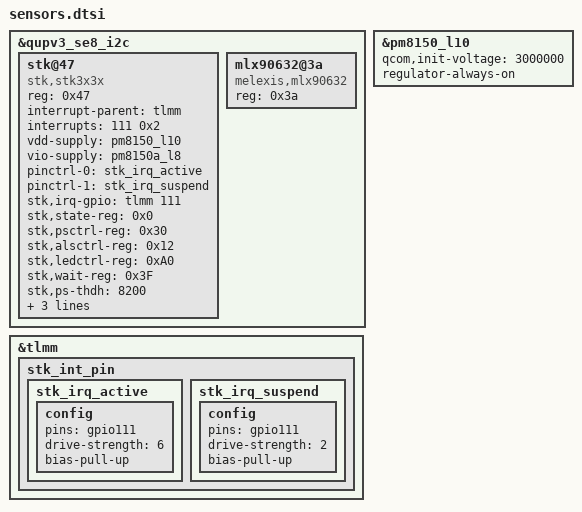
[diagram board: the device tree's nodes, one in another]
/*
 * nubia overwrite dts
 */

&qupv3_se8_i2c {
	status = "ok";
	stk@47 {
		compatible = "stk,stk3x3x";
		reg = <0x47>;
		interrupt-parent = <&tlmm>;
		interrupts = <111 0x2>;
		vdd-supply = <&pm8150_l10>; /*3.0v*/
		vio-supply = <&pm8150a_l8>; /*1.8v*/
		pinctrl-names = "stk_irq_active","stk_irq_suspend";
		pinctrl-0 = <&stk_irq_active>;
		pinctrl-1 = <&stk_irq_suspend>;
		stk,irq-gpio = <&tlmm 111 0x02>;
		stk,state-reg = <0x0>;
		stk,psctrl-reg = <0x30>;
		stk,alsctrl-reg = <0x12>;
		stk,ledctrl-reg = <0xA0>;
		stk,wait-reg = <0x3F>;
		stk,ps-thdh = <8200>;
		stk,ps-thdl = <8000>;
		stk,transmittance = <500>;
		stk,use-fir;
	};

	mlx90632@3a  {
		compatible = "melexis,mlx90632";
		reg = <0x3a>;
	};
};

&pm8150_l10 {
    status = "ok";
    qcom,init-voltage = <3000000>;
    regulator-always-on;
};
&tlmm {
	stk_int_pin {
		stk_irq_active: stk_irq_active {
			config {
				pins = "gpio111";
				drive-strength = <6>;
				bias-pull-up;
			};
		};
		stk_irq_suspend: stk_irq_suspend {
			config {
				pins = "gpio111";
				drive-strength = <2>;
				bias-pull-up;
			};
		};
	};


};
